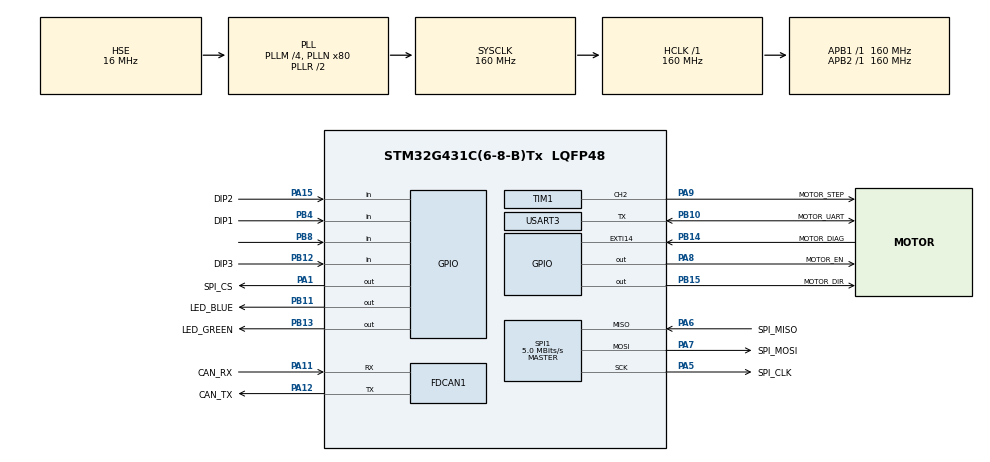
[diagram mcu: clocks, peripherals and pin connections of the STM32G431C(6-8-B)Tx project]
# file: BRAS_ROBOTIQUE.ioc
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Dma.Request0=SPI1_RX
Dma.Request1=SPI1_TX
Dma.SPI1_RX.0.Direction=DMA_PERIPH_TO_MEMORY
Dma.SPI1_RX.0.EventEnable=DISABLE
Dma.SPI1_RX.0.Instance=DMA1_Channel1
Dma.SPI1_RX.0.MemDataAlignment=DMA_MDATAALIGN_HALFWORD
Dma.SPI1_RX.0.MemInc=DMA_MINC_ENABLE
Dma.SPI1_RX.0.Mode=DMA_NORMAL
Dma.SPI1_RX.0.PeriphDataAlignment=DMA_PDATAALIGN_HALFWORD
Dma.SPI1_RX.0.PeriphInc=DMA_PINC_DISABLE
Dma.SPI1_RX.0.Polarity=HAL_DMAMUX_REQ_GEN_RISING
Dma.SPI1_RX.0.Priority=DMA_PRIORITY_HIGH
Dma.SPI1_RX.0.RequestNumber=1
Dma.SPI1_RX.0.SignalID=NONE
Dma.SPI1_RX.0.SyncEnable=DISABLE
Dma.SPI1_RX.0.SyncPolarity=HAL_DMAMUX_SYNC_NO_EVENT
Dma.SPI1_RX.0.SyncRequestNumber=1
Dma.SPI1_RX.0.SyncSignalID=NONE
Dma.SPI1_TX.1.Direction=DMA_MEMORY_TO_PERIPH
Dma.SPI1_TX.1.EventEnable=DISABLE
Dma.SPI1_TX.1.Instance=DMA1_Channel2
Dma.SPI1_TX.1.MemDataAlignment=DMA_MDATAALIGN_HALFWORD
Dma.SPI1_TX.1.MemInc=DMA_MINC_ENABLE
Dma.SPI1_TX.1.Mode=DMA_NORMAL
Dma.SPI1_TX.1.PeriphDataAlignment=DMA_PDATAALIGN_HALFWORD
Dma.SPI1_TX.1.PeriphInc=DMA_PINC_DISABLE
Dma.SPI1_TX.1.Polarity=HAL_DMAMUX_REQ_GEN_RISING
Dma.SPI1_TX.1.Priority=DMA_PRIORITY_LOW
Dma.SPI1_TX.1.RequestNumber=1
Dma.SPI1_TX.1.SignalID=NONE
Dma.SPI1_TX.1.SyncEnable=DISABLE
Dma.SPI1_TX.1.SyncPolarity=HAL_DMAMUX_SYNC_NO_EVENT
Dma.SPI1_TX.1.SyncRequestNumber=1
Dma.SPI1_TX.1.SyncSignalID=NONE
FDCAN1.AutoRetransmission=ENABLE
FDCAN1.CalculateBaudRateNominal=1111111
FDCAN1.CalculateTimeBitNominal=900
FDCAN1.CalculateTimeQuantumNominal=12.5
FDCAN1.DataPrescaler=1
FDCAN1.DataSyncJumpWidth=4
FDCAN1.DataTimeSeg1=11
FDCAN1.DataTimeSeg2=4
FDCAN1.FrameFormat=FDCAN_FRAME_FD_BRS
FDCAN1.NominalPrescaler=1
FDCAN1.NominalSyncJumpWidth=8
FDCAN1.NominalTimeSeg1=63
FDCAN1.NominalTimeSeg2=8
FDCAN1.StdFiltersNbr=2
FDCAN1.TxFifoQueueMode=FDCAN_TX_QUEUE_OPERATION
Mcu.Family=STM32G4
Mcu.Name=STM32G431C(6-8-B)Tx
Mcu.Package=LQFP48
NVIC.DMA1_Channel1_IRQn=true\:0\:0\:false\:false\:true\:false\:true\:true
NVIC.DMA1_Channel2_IRQn=true\:0\:0\:false\:false\:true\:false\:true\:true
NVIC.EXTI15_10_IRQn=true\:0\:0\:false\:false\:true\:true\:true\:true
NVIC.FDCAN1_IT0_IRQn=true\:2\:0\:true\:false\:true\:true\:true\:true
NVIC.PriorityGroup=NVIC_PRIORITYGROUP_4
NVIC.SPI1_IRQn=true\:1\:0\:true\:false\:true\:true\:true\:true
NVIC.TIM1_CC_IRQn=true\:1\:0\:true\:false\:true\:true\:true\:true
NVIC.USART3_IRQn=true\:3\:0\:true\:false\:true\:true\:true\:true
PA1.GPIO_Label=SPI_CS
PA1.GPIO_Speed=GPIO_SPEED_FREQ_HIGH
PA1.PinState=GPIO_PIN_SET
PA1.Signal=GPIO_Output
PA11.GPIO_Label=CAN_RX
PA11.GPIO_Speed=GPIO_SPEED_FREQ_VERY_HIGH
PA11.Mode=FDCAN_Activate
PA11.Signal=FDCAN1_RX
PA12.GPIO_Label=CAN_TX
PA12.GPIO_Speed=GPIO_SPEED_FREQ_VERY_HIGH
PA12.Mode=FDCAN_Activate
PA12.Signal=FDCAN1_TX
PA13.GPIO_Label=SWDIO
PA13.Mode=Trace_Asynchronous_SW
PA13.Signal=SYS_JTMS-SWDIO
PA14.GPIO_Label=SWCLK
PA14.Mode=Trace_Asynchronous_SW
PA14.Signal=SYS_JTCK-SWCLK
PA15.GPIO_Label=DIP2
PA15.Signal=GPIO_Input
PA5.GPIO_Label=SPI_CLK
PA5.GPIO_Speed=GPIO_SPEED_FREQ_VERY_HIGH
PA5.Mode=Full_Duplex_Master
PA5.Signal=SPI1_SCK
PA6.GPIO_Label=SPI_MISO
PA6.GPIO_Speed=GPIO_SPEED_FREQ_VERY_HIGH
PA6.Mode=Full_Duplex_Master
PA6.Signal=SPI1_MISO
PA7.GPIO_Label=SPI_MOSI
PA7.GPIO_Speed=GPIO_SPEED_FREQ_VERY_HIGH
PA7.Mode=Full_Duplex_Master
PA7.Signal=SPI1_MOSI
PA8.GPIO_Label=MOTOR_EN
PA8.GPIO_Speed=GPIO_SPEED_FREQ_LOW
PA8.PinState=GPIO_PIN_SET
PA8.Signal=GPIO_Output
PA9.GPIO_Label=MOTOR_STEP
PA9.GPIO_Speed=GPIO_SPEED_FREQ_VERY_HIGH
PA9.Signal=S_TIM1_CH2
PB10.GPIO_Label=MOTOR_UART
PB10.Mode=Half_duplex(single_wire_mode)
PB10.Signal=USART3_TX
PB11.GPIO_Label=LED_BLUE
PB11.Signal=GPIO_Output
PB12.GPIO_Label=DIP3
PB12.Signal=GPIO_Input
PB13.GPIO_Label=LED_GREEN
PB13.Signal=GPIO_Output
PB14.GPIO_Label=MOTOR_DIAG
PB14.Signal=GPXTI14
PB15.GPIO_Label=MOTOR_DIR
PB15.Signal=GPIO_Output
PB3.GPIO_Label=SWO
PB3.Mode=Trace_Asynchronous_SW
PB3.Signal=SYS_JTDO-SWO
PB4.GPIO_Label=DIP1
PB4.Signal=GPIO_Input
PB8-BOOT0.Signal=GPIO_Input
PF0-OSC_IN.Mode=HSE-External-Oscillator
PF0-OSC_IN.Signal=RCC_OSC_IN
PF1-OSC_OUT.Mode=HSE-External-Oscillator
PF1-OSC_OUT.Signal=RCC_OSC_OUT
ProjectManager.HeapSize=0x200
ProjectManager.StackSize=0x400
ProjectManager.TargetToolchain=STM32CubeIDE
RCC.ADC12Freq_Value=160000000
RCC.AHBFreq_Value=160000000
RCC.APB1Freq_Value=160000000
RCC.APB1TimFreq_Value=160000000
RCC.APB2Freq_Value=160000000
RCC.APB2TimFreq_Value=160000000
RCC.CortexFreq_Value=160000000
RCC.EXTERNAL_CLOCK_VALUE=12288000
RCC.FDCANCLockSelection=RCC_FDCANCLKSOURCE_PLL
RCC.HCLKFreq_Value=160000000
RCC.HSE_VALUE=16000000
RCC.HSI48_VALUE=48000000
RCC.HSI_VALUE=16000000
RCC.LSE_VALUE=32768
RCC.PLLM=RCC_PLLM_DIV4
RCC.PLLN=80
RCC.PLLQ=RCC_PLLQ_DIV4
RCC.PLLSourceVirtual=RCC_PLLSOURCE_HSE
RCC.SYSCLKFreq_VALUE=160000000
RCC.SYSCLKSource=RCC_SYSCLKSOURCE_PLLCLK
RCC.USBFreq_Value=80000000
RCC.VCOOutputFreq_Value=320000000
SH.S_TIM1_CH2.0=TIM1_CH2,PWM Generation2 CH2
SPI1.BaudRatePrescaler=SPI_BAUDRATEPRESCALER_32
SPI1.CLKPhase=SPI_PHASE_2EDGE
SPI1.CRCCalculation=SPI_CRCCALCULATION_DISABLE
SPI1.CalculateBaudRate=5.0 MBits/s
SPI1.DataSize=SPI_DATASIZE_16BIT
SPI1.Direction=SPI_DIRECTION_2LINES
SPI1.Mode=SPI_MODE_MASTER
SPI1.VirtualType=VM_MASTER
TIM1.AutoReloadPreload=TIM_AUTORELOAD_PRELOAD_ENABLE
TIM1.Channel-PWM\ Generation2\ CH2=TIM_CHANNEL_2
TIM1.PeriodNoDither=500 - 1
TIM1.Prescaler=160 - 1
TIM1.PulseNoDither_2=250
USART3.VirtualMode-Half_duplex(single_wire_mode)=VM_ASYNC
VP_CORDIC_VS_CORDIC.Mode=CORDIC_Activate
VP_SYS_VS_DBSignals.Mode=DisableDeadBatterySignals
VP_TIM1_VS_ClockSourceINT.Mode=Internal
board=custom

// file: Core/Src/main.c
/* USER CODE BEGIN Header */
/**
  ******************************************************************************
  * @file           : main.c
  * @brief          : Main program body
  ******************************************************************************
  * @attention
  *
  * Copyright (c) 2026 STMicroelectronics.
  * All rights reserved.
  *
  * This software is licensed under terms that can be found in the LICENSE file
  * in the root directory of this software component.
  * If no LICENSE file comes with this software, it is provided AS-IS.
  *
  ******************************************************************************
  */
/* USER CODE END Header */
#include "main.h"
#include "cordic.h"
#include "dma.h"
#include "fdcan.h"
#include "spi.h"
#include "tim.h"
#include "usart.h"
#include "gpio.h"

/* USER CODE BEGIN Includes */
#include "application.h"
#include "board_io.h"
/* USER CODE END Includes */

void SystemClock_Config(void);

int main(void)
{

  /* MCU Configuration--------------------------------------------------------*/

  /* Reset of all peripherals, Initializes the Flash interface and the Systick. */
  HAL_Init();

  /* Configure the system clock */
  SystemClock_Config();

  /* Initialize all configured peripherals */
  MX_GPIO_Init();
  MX_DMA_Init();
  MX_FDCAN1_Init();
  MX_SPI1_Init();
  MX_TIM1_Init();
  MX_USART3_UART_Init();
  MX_CORDIC_Init();
  /* USER CODE BEGIN 2 */
  if (Application_Start(&hspi1, &huart3, &htim1) != APP_INIT_OK)
  {
    //HAL_GPIO_WritePin(LED_GREEN_GPIO_Port, LED_GREEN_Pin, GPIO_PIN_SET);
  }
  /* USER CODE END 2 */

  /* Infinite loop */
  while (1)
  {

    /* USER CODE BEGIN 3 */
    Application_Loop();
  }
  /* USER CODE END 3 */
}

void SystemClock_Config(void)
{
  RCC_OscInitTypeDef RCC_OscInitStruct = {0};
  RCC_ClkInitTypeDef RCC_ClkInitStruct = {0};

  /** Configure the main internal regulator output voltage
  */
  HAL_PWREx_ControlVoltageScaling(PWR_REGULATOR_VOLTAGE_SCALE1_BOOST);

  /** Initializes the RCC Oscillators according to the specified parameters
  * in the RCC_OscInitTypeDef structure.
  */
  RCC_OscInitStruct.OscillatorType = RCC_OSCILLATORTYPE_HSE;
  RCC_OscInitStruct.HSEState = RCC_HSE_ON;
  RCC_OscInitStruct.PLL.PLLState = RCC_PLL_ON;
  RCC_OscInitStruct.PLL.PLLSource = RCC_PLLSOURCE_HSE;
  RCC_OscInitStruct.PLL.PLLM = RCC_PLLM_DIV4;
  RCC_OscInitStruct.PLL.PLLN = 80;
  RCC_OscInitStruct.PLL.PLLP = RCC_PLLP_DIV2;
  RCC_OscInitStruct.PLL.PLLQ = RCC_PLLQ_DIV4;
  RCC_OscInitStruct.PLL.PLLR = RCC_PLLR_DIV2;
  if (HAL_RCC_OscConfig(&RCC_OscInitStruct) != HAL_OK)
  {
    Error_Handler();
  }

  /** Initializes the CPU, AHB and APB buses clocks
  */
  RCC_ClkInitStruct.ClockType = RCC_CLOCKTYPE_HCLK|RCC_CLOCKTYPE_SYSCLK
                              |RCC_CLOCKTYPE_PCLK1|RCC_CLOCKTYPE_PCLK2;
  RCC_ClkInitStruct.SYSCLKSource = RCC_SYSCLKSOURCE_PLLCLK;
  RCC_ClkInitStruct.AHBCLKDivider = RCC_SYSCLK_DIV1;
  RCC_ClkInitStruct.APB1CLKDivider = RCC_HCLK_DIV1;
  RCC_ClkInitStruct.APB2CLKDivider = RCC_HCLK_DIV1;

  if (HAL_RCC_ClockConfig(&RCC_ClkInitStruct, FLASH_LATENCY_4) != HAL_OK)
  {
    Error_Handler();
  }
}

void Error_Handler(void)
{
  __disable_irq();
}
